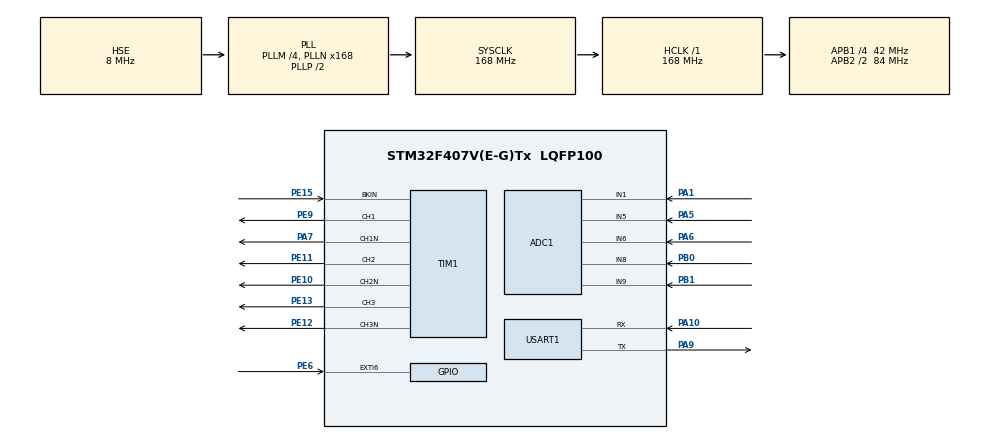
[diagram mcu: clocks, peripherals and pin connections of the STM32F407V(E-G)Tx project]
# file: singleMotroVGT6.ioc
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ADC1.Channel-0\#ChannelRegularConversion=ADC_CHANNEL_1
ADC1.Channel-1\#ChannelRegularConversion=ADC_CHANNEL_5
ADC1.Channel-2\#ChannelInjectedConversion=ADC_CHANNEL_8
ADC1.Channel-3\#ChannelInjectedConversion=ADC_CHANNEL_9
ADC1.Channel-4\#ChannelInjectedConversion=ADC_CHANNEL_6
ADC1.ClockPrescaler=ADC_CLOCK_SYNC_PCLK_DIV4
ADC1.DataAlign=ADC_DATAALIGN_LEFT
ADC1.ExternalTrigInjecConv=ADC_EXTERNALTRIGINJECCONV_T1_CC4
ADC1.InjNumberOfConversion=3
ADC1.InjectedOffset-2\#ChannelInjectedConversion=0
ADC1.InjectedOffset-3\#ChannelInjectedConversion=0
ADC1.InjectedOffset-4\#ChannelInjectedConversion=0
ADC1.InjectedRank-2\#ChannelInjectedConversion=1
ADC1.InjectedRank-3\#ChannelInjectedConversion=2
ADC1.InjectedRank-4\#ChannelInjectedConversion=3
ADC1.NbrOfConversion=2
ADC1.NbrOfConversionFlag=1
ADC1.Rank-0\#ChannelRegularConversion=1
ADC1.Rank-1\#ChannelRegularConversion=2
ADC1.SamplingTime-0\#ChannelRegularConversion=ADC_SAMPLETIME_3CYCLES
ADC1.SamplingTime-1\#ChannelRegularConversion=ADC_SAMPLETIME_3CYCLES
ADC1.SamplingTime-2\#ChannelInjectedConversion=ADC_SAMPLETIME_3CYCLES
ADC1.SamplingTime-3\#ChannelInjectedConversion=ADC_SAMPLETIME_3CYCLES
ADC1.SamplingTime-4\#ChannelInjectedConversion=ADC_SAMPLETIME_3CYCLES
ADC1.ScanConvMode=ENABLE
ADC1.master=1
ADC2.Channel-1\#ChannelRegularConversion=ADC_CHANNEL_8
ADC2.Channel-2\#ChannelInjectedConversion=ADC_CHANNEL_8
ADC2.Channel-3\#ChannelInjectedConversion=ADC_CHANNEL_9
ADC2.Channel-4\#ChannelInjectedConversion=ADC_CHANNEL_6
ADC2.ClockPrescaler=ADC_CLOCK_SYNC_PCLK_DIV4
ADC2.ExternalTrigInjecConv=ADC_EXTERNALTRIGINJECCONV_T1_CC4
ADC2.InjNumberOfConversion=3
ADC2.InjectedConvMode=Discontinuous
ADC2.InjectedOffset-2\#ChannelInjectedConversion=0
ADC2.InjectedOffset-3\#ChannelInjectedConversion=0
ADC2.InjectedOffset-4\#ChannelInjectedConversion=0
ADC2.InjectedRank-2\#ChannelInjectedConversion=1
ADC2.InjectedRank-3\#ChannelInjectedConversion=2
ADC2.InjectedRank-4\#ChannelInjectedConversion=3
ADC2.NbrOfConversionFlag=1
ADC2.Rank-1\#ChannelRegularConversion=1
ADC2.SamplingTime-1\#ChannelRegularConversion=ADC_SAMPLETIME_3CYCLES
ADC2.SamplingTime-2\#ChannelInjectedConversion=ADC_SAMPLETIME_3CYCLES
ADC2.SamplingTime-3\#ChannelInjectedConversion=ADC_SAMPLETIME_3CYCLES
ADC2.SamplingTime-4\#ChannelInjectedConversion=ADC_SAMPLETIME_3CYCLES
ADC2.ScanConvMode=ENABLE
Mcu.Family=STM32F4
Mcu.Name=STM32F407V(E-G)Tx
Mcu.Package=LQFP100
NVIC.ADC_IRQn=true\:2\:0\:true\:true\:false\:1\:true\:true
NVIC.EXTI9_5_IRQn=true\:3\:0\:true\:true\:false\:2\:true\:true
NVIC.PriorityGroup=NVIC_PRIORITYGROUP_4
NVIC.TIM1_BRK_TIM9_IRQn=true\:4\:0\:true\:true\:false\:3\:true\:true
NVIC.TIM1_UP_TIM10_IRQn=true\:0\:0\:false\:true\:false\:4\:true\:true
NVIC.USART1_IRQn=true\:3\:0\:true\:true\:false\:5\:true\:true
PA1.Signal=ADCx_IN1
PA10.Mode=Asynchronous
PA10.Signal=USART1_RX
PA13.Mode=Trace_Asynchronous_SW
PA13.Signal=SYS_JTMS-SWDIO
PA14.Mode=Trace_Asynchronous_SW
PA14.Signal=SYS_JTCK-SWCLK
PA5.Signal=ADCx_IN5
PA6.Signal=ADCx_IN6
PA7.Mode=PWM Generation1 CH1 CH1N
PA7.Signal=TIM1_CH1N
PA9.Mode=Asynchronous
PA9.Signal=USART1_TX
PB0.Signal=ADCx_IN8
PB1.Signal=ADCx_IN9
PB3.Mode=Trace_Asynchronous_SW
PB3.Signal=SYS_JTDO-SWO
PE10.Mode=PWM Generation2 CH2 CH2N
PE10.Signal=TIM1_CH2N
PE11.Signal=S_TIM1_CH2
PE12.Mode=PWM Generation3 CH3 CH3N
PE12.Signal=TIM1_CH3N
PE13.Signal=S_TIM1_CH3
PE15.Mode=Activate-Break-Input
PE15.Signal=TIM1_BKIN
PE6.Signal=GPXTI6
PE9.Signal=S_TIM1_CH1
PH0-OSC_IN.Mode=HSE-External-Oscillator
PH0-OSC_IN.Signal=RCC_OSC_IN
PH1-OSC_OUT.Mode=HSE-External-Oscillator
PH1-OSC_OUT.Signal=RCC_OSC_OUT
ProjectManager.HeapSize=0x200
ProjectManager.StackSize=0x400
ProjectManager.TargetToolchain=MDK-ARM V5
RCC.48MHZClocksFreq_Value=84000000
RCC.AHBFreq_Value=168000000
RCC.APB1CLKDivider=RCC_HCLK_DIV4
RCC.APB1Freq_Value=42000000
RCC.APB1TimFreq_Value=84000000
RCC.APB2CLKDivider=RCC_HCLK_DIV2
RCC.APB2Freq_Value=84000000
RCC.APB2TimFreq_Value=168000000
RCC.CortexFreq_Value=168000000
RCC.HCLKFreq_Value=168000000
RCC.HSE_VALUE=8000000
RCC.HSI_VALUE=16000000
RCC.LSE_VALUE=32768
RCC.PLLM=4
RCC.PLLN=168
RCC.PLLSourceVirtual=RCC_PLLSOURCE_HSE
RCC.SYSCLKFreq_VALUE=168000000
RCC.SYSCLKSource=RCC_SYSCLKSOURCE_PLLCLK
RCC.VCOOutputFreq_Value=336000000
SH.ADCx_IN1.0=ADC1_IN1,IN1
SH.ADCx_IN5.0=ADC1_IN5,IN5
SH.ADCx_IN6.0=ADC1_IN6,IN6
SH.ADCx_IN6.1=ADC2_IN6,IN6
SH.ADCx_IN8.0=ADC1_IN8,IN8
SH.ADCx_IN8.1=ADC2_IN8,IN8
SH.ADCx_IN9.0=ADC1_IN9,IN9
SH.ADCx_IN9.1=ADC2_IN9,IN9
SH.S_TIM1_CH1.0=TIM1_CH1,PWM Generation1 CH1 CH1N
SH.S_TIM1_CH2.0=TIM1_CH2,PWM Generation2 CH2 CH2N
SH.S_TIM1_CH3.0=TIM1_CH3,PWM Generation3 CH3 CH3N
TIM1.BreakPolarity=TIM_BREAKPOLARITY_LOW
TIM1.Channel-PWM\ Generation1\ CH1\ CH1N=TIM_CHANNEL_1
TIM1.Channel-PWM\ Generation2\ CH2\ CH2N=TIM_CHANNEL_2
TIM1.Channel-PWM\ Generation3\ CH3\ CH3N=TIM_CHANNEL_3
TIM1.Channel-PWM\ Generation4\ No\ Output=TIM_CHANNEL_4
TIM1.ClockDivision=TIM_CLOCKDIVISION_DIV2
TIM1.CounterMode=TIM_COUNTERMODE_CENTERALIGNED1
TIM1.DeadTime=((DEAD_TIME_COUNTS) / 2)
TIM1.LockLevel=TIM_LOCKLEVEL_1
TIM1.OCMode_PWM-PWM\ Generation4\ No\ Output=TIM_OCMODE_PWM2
TIM1.OffStateIDLEMode=TIM_OSSI_ENABLE
TIM1.OffStateRunMode=TIM_OSSR_ENABLE
TIM1.Period=((PWM_PERIOD_CYCLES) / 2)
TIM1.Prescaler=((TIM_CLOCK_DIVIDER) - 1)
TIM1.Pulse-PWM\ Generation4\ No\ Output=(((PWM_PERIOD_CYCLES) / 2) - (HTMIN))
TIM1.RepetitionCounter=(REP_COUNTER)
USART1.VirtualMode=VM_ASYNC
VP_TIM1_VS_ClockSourceITR.Mode=TriggerSource_ITR1
VP_TIM1_VS_ControllerModeTrigger.Mode=Trigger Mode
VP_TIM1_VS_no_output4.Mode=PWM Generation4 No Output
board=custom

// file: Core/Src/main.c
/* USER CODE BEGIN Header */
/**
  ******************************************************************************
  * @file           : main.c
  * @brief          : Main program body
  ******************************************************************************
  * @attention
  *
  * <h2><center>&copy; Copyright (c) 2021 STMicroelectronics.
  * All rights reserved.</center></h2>
  *
  * This software component is licensed by ST under BSD 3-Clause license,
  * the "License"; You may not use this file except in compliance with the
  * License. You may obtain a copy of the License at:
  *                        opensource.org/licenses/BSD-3-Clause
  *
  ******************************************************************************
  */
/* USER CODE END Header */
#include "main.h"

/* USER CODE BEGIN Includes */
#include "motorcontrol.h"
#include "mc_tasks.h"
/* USER CODE END Includes */

ADC_HandleTypeDef hadc1;
ADC_HandleTypeDef hadc2;

TIM_HandleTypeDef htim1;

UART_HandleTypeDef huart1;

void SystemClock_Config(void);
static void MX_GPIO_Init(void);
static void MX_ADC1_Init(void);
static void MX_ADC2_Init(void);
static void MX_TIM1_Init(void);
static void MX_USART1_UART_Init(void);
static void MX_NVIC_Init(void);

/* USER CODE BEGIN 0 */

uint16_t ad[4];
/* USER CODE END 0 */

int main(void)
{

  /* MCU Configuration--------------------------------------------------------*/

  /* Reset of all peripherals, Initializes the Flash interface and the Systick. */
  HAL_Init();

  /* Configure the system clock */
  SystemClock_Config();

  /* Initialize all configured peripherals */
  MX_GPIO_Init();
  MX_ADC1_Init();
  MX_ADC2_Init();
  MX_TIM1_Init();
  MX_USART1_UART_Init();

  /* Initialize interrupts */
  MX_NVIC_Init();
  /* USER CODE BEGIN 2 */
	MX_MotorControl_Init();
  /* USER CODE END 2 */

  /* Infinite loop */
  while (1)
  {
    /* USER CODE BEGIN 3 */
		//test pwm

  }
  /* USER CODE END 3 */
}

void SystemClock_Config(void)
{
  RCC_OscInitTypeDef RCC_OscInitStruct = {0};
  RCC_ClkInitTypeDef RCC_ClkInitStruct = {0};

  /** Configure the main internal regulator output voltage
  */
  __HAL_RCC_PWR_CLK_ENABLE();
  __HAL_PWR_VOLTAGESCALING_CONFIG(PWR_REGULATOR_VOLTAGE_SCALE1);
  /** Initializes the RCC Oscillators according to the specified parameters
  * in the RCC_OscInitTypeDef structure.
  */
  RCC_OscInitStruct.OscillatorType = RCC_OSCILLATORTYPE_HSE;
  RCC_OscInitStruct.HSEState = RCC_HSE_ON;
  RCC_OscInitStruct.PLL.PLLState = RCC_PLL_ON;
  RCC_OscInitStruct.PLL.PLLSource = RCC_PLLSOURCE_HSE;
  RCC_OscInitStruct.PLL.PLLM = 4;
  RCC_OscInitStruct.PLL.PLLN = 168;
  RCC_OscInitStruct.PLL.PLLP = RCC_PLLP_DIV2;
  RCC_OscInitStruct.PLL.PLLQ = 4;
  if (HAL_RCC_OscConfig(&RCC_OscInitStruct) != HAL_OK)
  {
    Error_Handler();
  }
  /** Initializes the CPU, AHB and APB buses clocks
  */
  RCC_ClkInitStruct.ClockType = RCC_CLOCKTYPE_HCLK|RCC_CLOCKTYPE_SYSCLK
                              |RCC_CLOCKTYPE_PCLK1|RCC_CLOCKTYPE_PCLK2;
  RCC_ClkInitStruct.SYSCLKSource = RCC_SYSCLKSOURCE_PLLCLK;
  RCC_ClkInitStruct.AHBCLKDivider = RCC_SYSCLK_DIV1;
  RCC_ClkInitStruct.APB1CLKDivider = RCC_HCLK_DIV4;
  RCC_ClkInitStruct.APB2CLKDivider = RCC_HCLK_DIV2;

  if (HAL_RCC_ClockConfig(&RCC_ClkInitStruct, FLASH_LATENCY_5) != HAL_OK)
  {
    Error_Handler();
  }
}

/**
  * @brief NVIC Configuration.
  * @retval None
  */
static void MX_NVIC_Init(void)
{
  /* ADC_IRQn interrupt configuration */
	//中断优先级设置 2代表抢占优先级 0代表优先级 数字越小优先级越高
	//抢占优先级相同时 检测优先级，数字越小就执行此中断
  HAL_NVIC_SetPriority(ADC_IRQn, 2, 0);//设置AD优先级
  HAL_NVIC_EnableIRQ(ADC_IRQn);//使能ad中断
  /* EXTI9_5_IRQn interrupt configuration */
  HAL_NVIC_SetPriority(EXTI9_5_IRQn, 3, 0);//外部触发中断
  HAL_NVIC_EnableIRQ(EXTI9_5_IRQn);//使能
  /* TIM1_BRK_TIM9_IRQn interrupt configuration */
  HAL_NVIC_SetPriority(TIM1_BRK_TIM9_IRQn, 4, 0);//刹车中断brk引脚有信号时停止所有pwm的输出（st单片机自带的功能）
  HAL_NVIC_EnableIRQ(TIM1_BRK_TIM9_IRQn);
  /* TIM1_UP_TIM10_IRQn interrupt configuration */
  HAL_NVIC_SetPriority(TIM1_UP_TIM10_IRQn, 0, 0);//定时器向上计数溢出中断，这时候下管全部打开 可以进行ad采样
  HAL_NVIC_EnableIRQ(TIM1_UP_TIM10_IRQn);
  /* USART1_IRQn interrupt configuration */
  HAL_NVIC_SetPriority(USART1_IRQn, 3, 0);//串口优先级
  HAL_NVIC_EnableIRQ(USART1_IRQn);
}

static void MX_ADC1_Init(void)
{

  ADC_ChannelConfTypeDef sConfig = {0};
  ADC_InjectionConfTypeDef sConfigInjected = {0};

  /** Configure the global features of the ADC (Clock, Resolution, Data Alignment and number of conversion)
  */
  hadc1.Instance = ADC1;
  hadc1.Init.ClockPrescaler = ADC_CLOCK_SYNC_PCLK_DIV4;//时钟树种adc clock = PCLK2/4 = 84/4 = 21M
	//采样速率 12位采样周期 3（可设置最小）+12（固定）周期
	//15/21m = 0.7us 完成一次采样
  hadc1.Init.Resolution = ADC_RESOLUTION_12B;//设置12位分辨率
  hadc1.Init.ScanConvMode = ENABLE;//扫描模式使能 cube中只有使能配置 对于注入模式没有关系
  hadc1.Init.ContinuousConvMode = DISABLE; //连续转换模式关
  hadc1.Init.DiscontinuousConvMode = DISABLE;//非连续转换模式（单次转换模式）关
  hadc1.Init.ExternalTrigConvEdge = ADC_EXTERNALTRIGCONVEDGE_NONE;//无外部触发源
  hadc1.Init.ExternalTrigConv = ADC_SOFTWARE_START;//软件设置转化开始
  hadc1.Init.DataAlign = ADC_DATAALIGN_LEFT;//数据类型左对齐 在使用时候需要右侧移动（在电流采样中有体现）
  hadc1.Init.NbrOfConversion = 2;//转换通道2个 分别为温度和总线电压
  hadc1.Init.DMAContinuousRequests = DISABLE;//DMA功能关闭
  hadc1.Init.EOCSelection = ADC_EOC_SINGLE_CONV;//单通道转换结束职位标志
  if (HAL_ADC_Init(&hadc1) != HAL_OK)
  {
    Error_Handler();
  }
  /** Configure for the selected ADC regular channel its corresponding rank in the sequencer and its sample time.
  */
  sConfig.Channel = ADC_CHANNEL_1;//规则转换通道1设置
  sConfig.Rank = 1;//排列第一位
  sConfig.SamplingTime = ADC_SAMPLETIME_3CYCLES;//采样时间
  if (HAL_ADC_ConfigChannel(&hadc1, &sConfig) != HAL_OK)
  {
    Error_Handler();
  }
  /** Configure for the selected ADC regular channel its corresponding rank in the sequencer and its sample time.
  */
  sConfig.Channel = ADC_CHANNEL_5;
  sConfig.Rank = 2;
  if (HAL_ADC_ConfigChannel(&hadc1, &sConfig) != HAL_OK)
  {
    Error_Handler();
  }
  /** Configures for the selected ADC injected channel its corresponding rank in the sequencer and its sample time
  */
  sConfigInjected.InjectedChannel = ADC_CHANNEL_8;//注入模式通道8设置
  sConfigInjected.InjectedRank = 1;//设置为队列1
  sConfigInjected.InjectedNbrOfConversion = 3;//注入通道转换数量共三个通道
  sConfigInjected.InjectedSamplingTime = ADC_SAMPLETIME_3CYCLES;//采样后期设置为3个周期
  sConfigInjected.ExternalTrigInjecConvEdge = ADC_EXTERNALTRIGINJECCONVEDGE_RISING;//外部上升沿触发 后期为了适应采样窗口变小会更改下降沿触发
  sConfigInjected.ExternalTrigInjecConv = ADC_EXTERNALTRIGINJECCONV_T1_CC4;//设置ch4上升沿触发
  sConfigInjected.AutoInjectedConv = DISABLE;//关闭自动注入转换
  sConfigInjected.InjectedDiscontinuousConvMode = DISABLE;//关闭转换规则组后转换注入组功能
  sConfigInjected.InjectedOffset = 0;//注入偏执设定为0 如果设定1000 转换结果减去1000
  if (HAL_ADCEx_InjectedConfigChannel(&hadc1, &sConfigInjected) != HAL_OK)
  {
    Error_Handler();
  }
  /** Configures for the selected ADC injected channel its corresponding rank in the sequencer and its sample time
  */
  sConfigInjected.InjectedChannel = ADC_CHANNEL_9;
  sConfigInjected.InjectedRank = 2;
  if (HAL_ADCEx_InjectedConfigChannel(&hadc1, &sConfigInjected) != HAL_OK)
  {
    Error_Handler();
  }
  /** Configures for the selected ADC injected channel its corresponding rank in the sequencer and its sample time
  */
  sConfigInjected.InjectedChannel = ADC_CHANNEL_6;
  sConfigInjected.InjectedRank = 3;
  if (HAL_ADCEx_InjectedConfigChannel(&hadc1, &sConfigInjected) != HAL_OK)
  {
    Error_Handler();
  }

}

static void MX_ADC2_Init(void)
{

  ADC_ChannelConfTypeDef sConfig = {0};
  ADC_InjectionConfTypeDef sConfigInjected = {0};

  /** Configure the global features of the ADC (Clock, Resolution, Data Alignment and number of conversion)
  */
  hadc2.Instance = ADC2;
  hadc2.Init.ClockPrescaler = ADC_CLOCK_SYNC_PCLK_DIV4;
  hadc2.Init.Resolution = ADC_RESOLUTION_12B;
  hadc2.Init.ScanConvMode = ENABLE;
  hadc2.Init.ContinuousConvMode = DISABLE;
  hadc2.Init.DiscontinuousConvMode = DISABLE;
  hadc2.Init.ExternalTrigConvEdge = ADC_EXTERNALTRIGCONVEDGE_NONE;
  hadc2.Init.ExternalTrigConv = ADC_SOFTWARE_START;
  hadc2.Init.DataAlign = ADC_DATAALIGN_LEFT;
  hadc2.Init.NbrOfConversion = 1;
  hadc2.Init.DMAContinuousRequests = DISABLE;
  hadc2.Init.EOCSelection = ADC_EOC_SINGLE_CONV;
  if (HAL_ADC_Init(&hadc2) != HAL_OK)
  {
    Error_Handler();
  }
  /** Configure for the selected ADC regular channel its corresponding rank in the sequencer and its sample time.
  */
  sConfig.Channel = ADC_CHANNEL_8;
  sConfig.Rank = 1;
  sConfig.SamplingTime = ADC_SAMPLETIME_3CYCLES;
  if (HAL_ADC_ConfigChannel(&hadc2, &sConfig) != HAL_OK)
  {
    Error_Handler();
  }
  /** Configures for the selected ADC injected channel its corresponding rank in the sequencer and its sample time
  */
  sConfigInjected.InjectedChannel = ADC_CHANNEL_8;
  sConfigInjected.InjectedRank = 1;
  sConfigInjected.InjectedNbrOfConversion = 3;
  sConfigInjected.InjectedSamplingTime = ADC_SAMPLETIME_3CYCLES;
  sConfigInjected.ExternalTrigInjecConvEdge = ADC_EXTERNALTRIGINJECCONVEDGE_RISING;
  sConfigInjected.ExternalTrigInjecConv = ADC_EXTERNALTRIGINJECCONV_T1_CC4;
  sConfigInjected.AutoInjectedConv = DISABLE;
  sConfigInjected.InjectedDiscontinuousConvMode = ENABLE;
  sConfigInjected.InjectedOffset = 0;
  if (HAL_ADCEx_InjectedConfigChannel(&hadc2, &sConfigInjected) != HAL_OK)
  {
    Error_Handler();
  }
  /** Configures for the selected ADC injected channel its corresponding rank in the sequencer and its sample time
  */
  sConfigInjected.InjectedChannel = ADC_CHANNEL_9;
  sConfigInjected.InjectedRank = 2;
  if (HAL_ADCEx_InjectedConfigChannel(&hadc2, &sConfigInjected) != HAL_OK)
  {
    Error_Handler();
  }
  /** Configures for the selected ADC injected channel its corresponding rank in the sequencer and its sample time
  */
  sConfigInjected.InjectedChannel = ADC_CHANNEL_6;
  sConfigInjected.InjectedRank = 3;
  if (HAL_ADCEx_InjectedConfigChannel(&hadc2, &sConfigInjected) != HAL_OK)
  {
    Error_Handler();
  }

}

static void MX_TIM1_Init(void)
{

  TIM_SlaveConfigTypeDef sSlaveConfig = {0};
  TIM_MasterConfigTypeDef sMasterConfig = {0};
  TIM_OC_InitTypeDef sConfigOC = {0};
  TIM_BreakDeadTimeConfigTypeDef sBreakDeadTimeConfig = {0};

  htim1.Instance = TIM1;
  htim1.Init.Prescaler = ((TIM_CLOCK_DIVIDER) - 1);//时钟不分频
	//01：中央对齐模式1 计数器交替地向上和向下计数。输出比较中断标志位，只在计数器向下计数时被设置
  //10：中央对齐模式2 计数器交替地向上和向下计数。输出比较中断标志位，只在计数器向上计数时被设置
  //11：中央对齐模式3 计数器交替地向上和向下计数。输出比较中断标志位，只在计数器向下和向上计数时均被设置
  htim1.Init.CounterMode = TIM_COUNTERMODE_CENTERALIGNED1;//中央对其模式1
  htim1.Init.Period = ((PWM_PERIOD_CYCLES) / 2);// pwm周期是计数的2倍 因为从0 -cnt - 0 计数循环2次 pwm 执行1次
  htim1.Init.ClockDivision = TIM_CLOCKDIVISION_DIV2;
//RCR = 0，更新事件没有延迟；
//RCR = 1，更新事件延后了半个PWM周期；
//RCR = 2, 更新事件延后了一个PWM周期；
//RCR = 3，更新事件延后了3个PWM周期；
  htim1.Init.RepetitionCounter = (REP_COUNTER);//间隔一个0-htim1.Init.Period触发一车溢出中断 也可以用来产生固定数量的pwm波形
  htim1.Init.AutoReloadPreload = TIM_AUTORELOAD_PRELOAD_DISABLE;//关闭自动重载 一次赋值pwm占空比 只执行一个pwm周期直到下次赋值在执行
  if (HAL_TIM_Base_Init(&htim1) != HAL_OK)
  {
    Error_Handler();
  }
  if (HAL_TIM_PWM_Init(&htim1) != HAL_OK)
  {
    Error_Handler();
  }
  sSlaveConfig.SlaveMode = TIM_SLAVEMODE_TRIGGER;//不理解为什么配置成从模式
//TIM ITR0 (TS = 000)| ITR1 (TS = 001)| ITR2 (TS = 010)| ITR3 (TS = 011)
//TIM1 TIM5          | TIM2           | TIM3           | TIM4
//TIM8 TIM1          | TIM2           | TIM4           | TIM5
  sSlaveConfig.InputTrigger = TIM_TS_ITR1;//定时器2为出发源
  if (HAL_TIM_SlaveConfigSynchro(&htim1, &sSlaveConfig) != HAL_OK)
  {
    Error_Handler();
  }
  sMasterConfig.MasterOutputTrigger = TIM_TRGO_RESET;
  sMasterConfig.MasterSlaveMode = TIM_MASTERSLAVEMODE_DISABLE;//主从模式关闭 上面设置的从模式应该不起作用
  if (HAL_TIMEx_MasterConfigSynchronization(&htim1, &sMasterConfig) != HAL_OK)
  {
    Error_Handler();
  }

//PWM模式1
//在向上计数时，一旦TIMx_CNT
//在向下计数时，一旦TIMx_CNT>TIMx_CCR1时通道1（chx not chxn）为无效电平(OC1REF=0)，否则为有效 电平(OC1REF=1)。
//PWM模式2
//在向上计数时，一旦TIMx_CNT
//在向下计数时，一旦TIMx_CNT>TIMx_CCR1时通道1为有效电平，否则为无效电平
//模式1和模式2并无本质的区别，只是在同样的有效电平情况下，输出的波形电平相反而已
//什么是有效电平：OCxREF和CCXP共同决定引脚的输出电平，
	//CC1P与REF相同则输出为1，反之输出为0。
	//而CCXP的极性可以由TIM_OCInitStructure.TIM_OCPolarity这一结构体参量来控制
  sConfigOC.OCMode = TIM_OCMODE_PWM1;
  sConfigOC.Pulse = 0;//设置占空比
		//当CH Polarity为High时，高电平占宽度sConfigOC.Pulse
  //当CH Polarity为Low时，低电平占sConfigOC.Pulse
  sConfigOC.OCPolarity = TIM_OCPOLARITY_HIGH;//高电平

  sConfigOC.OCNPolarity = TIM_OCNPOLARITY_HIGH;
  sConfigOC.OCFastMode = TIM_OCFAST_DISABLE;//不知道干啥用的
//Set为高电平
//Reset为低电平
  sConfigOC.OCIdleState = TIM_OCIDLESTATE_RESET;//互补两通道
  sConfigOC.OCNIdleState = TIM_OCNIDLESTATE_RESET;
  if (HAL_TIM_PWM_ConfigChannel(&htim1, &sConfigOC, TIM_CHANNEL_1) != HAL_OK)
  {
    Error_Handler();
  }
  if (HAL_TIM_PWM_ConfigChannel(&htim1, &sConfigOC, TIM_CHANNEL_2) != HAL_OK)
  {
    Error_Handler();
  }
  if (HAL_TIM_PWM_ConfigChannel(&htim1, &sConfigOC, TIM_CHANNEL_3) != HAL_OK)
  {
    Error_Handler();
  }
  sConfigOC.OCMode = TIM_OCMODE_PWM2;//用来触发ad采样的通道四  设置pwm模式2
  sConfigOC.Pulse = (((PWM_PERIOD_CYCLES) / 2) - (HTMIN));//占空比设置成最大//如果倒三角技术就是占空比最大
  if (HAL_TIM_PWM_ConfigChannel(&htim1, &sConfigOC, TIM_CHANNEL_4) != HAL_OK)
  {
    Error_Handler();
  }
  sBreakDeadTimeConfig.OffStateRunMode = TIM_OSSR_ENABLE;
  sBreakDeadTimeConfig.OffStateIDLEMode = TIM_OSSI_ENABLE;
  sBreakDeadTimeConfig.LockLevel = TIM_LOCKLEVEL_1;
  sBreakDeadTimeConfig.DeadTime = ((DEAD_TIME_COUNTS) / 2);
  sBreakDeadTimeConfig.BreakState = TIM_BREAK_ENABLE;
  sBreakDeadTimeConfig.BreakPolarity = TIM_BREAKPOLARITY_LOW;
  sBreakDeadTimeConfig.AutomaticOutput = TIM_AUTOMATICOUTPUT_DISABLE;
  if (HAL_TIMEx_ConfigBreakDeadTime(&htim1, &sBreakDeadTimeConfig) != HAL_OK)
  {
    Error_Handler();
  }
  HAL_TIM_MspPostInit(&htim1);

}

static void MX_USART1_UART_Init(void)
{

  huart1.Instance = USART1;//串口1
  huart1.Init.BaudRate = 115200;//波特率
  huart1.Init.WordLength = UART_WORDLENGTH_8B;//8数据位
  huart1.Init.StopBits = UART_STOPBITS_1;//1停止位
  huart1.Init.Parity = UART_PARITY_NONE;
  huart1.Init.Mode = UART_MODE_TX_RX;
  huart1.Init.HwFlowCtl = UART_HWCONTROL_NONE;
  huart1.Init.OverSampling = UART_OVERSAMPLING_16;
  if (HAL_UART_Init(&huart1) != HAL_OK)
  {
    Error_Handler();
  }

}

static void MX_GPIO_Init(void)
{
  GPIO_InitTypeDef GPIO_InitStruct = {0};

  /* GPIO Ports Clock Enable */
  __HAL_RCC_GPIOE_CLK_ENABLE();
  __HAL_RCC_GPIOH_CLK_ENABLE();
  __HAL_RCC_GPIOA_CLK_ENABLE();
  __HAL_RCC_GPIOB_CLK_ENABLE();

  /*Configure GPIO pin : PE6 */
  GPIO_InitStruct.Pin = GPIO_PIN_6;
  GPIO_InitStruct.Mode = GPIO_MODE_IT_RISING;
  GPIO_InitStruct.Pull = GPIO_NOPULL;
  HAL_GPIO_Init(GPIOE, &GPIO_InitStruct);

}

void Error_Handler(void)
{
  __disable_irq();
  while (1)
  {
  }
}

/************************ (C) COPYRIGHT STMicroelectronics *****END OF FILE****/
